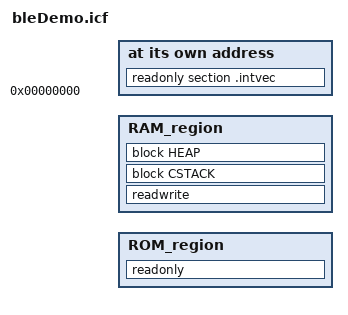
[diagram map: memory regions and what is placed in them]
/**** ICF symbol definitions */

/*-Specials-*/
define symbol __ICF_intvec_start__ = 0x00000000;

/*-Memory Regions-*/
define symbol __ICF_region_ROM_start__ = 0x00000000;
define symbol __ICF_region_ROM_end__   = (0x00000000+0x00040000-1);
define symbol __ICF_region_RAM_start__ = 0x20000000;
define symbol __ICF_region_RAM_end__   = (0x20000000+0x00008000-1);

/*-Sizes-*/
define symbol __ICF_size_cstack__ = 0x400;
define symbol __ICF_size_heap__   = 0x4000;

/**** End of ICF symbol definitions */

define memory mem with size = 4G;
define region ROM_region   = mem:[from __ICF_region_ROM_start__   to __ICF_region_ROM_end__];
define region RAM_region   = mem:[from __ICF_region_RAM_start__   to __ICF_region_RAM_end__];

define block CSTACK    with alignment = 8, size = __ICF_size_cstack__   { };
define block HEAP      with alignment = 8, size = __ICF_size_heap__     { };

initialize by copy { readwrite };
do not initialize  { section .noinit };

keep { section .intvec };
place at address mem:__ICF_intvec_start__ { readonly section .intvec };

place in ROM_region   { readonly };
place in RAM_region   { readwrite,
                        block CSTACK, 
                        block HEAP };
